# ATBTLC1000WLCSP register map
Vendor: Atmel Corp; Series: SAMB11; File version: TODO
CPU: CM0 r0p0, little endian, no MPU, no FPU, 2 interrupt priority bits
Address unit: 32 bits
Registers are 32-bit, read-write, reset 0x0 unless marked. A register's access mark holds for its fields unless they carry their own. Offsets are from the block's base; [hi:lo] are bit positions; {n}, {i} and the like mark numbered series.

## WDT0 — Watchdog0 Timer
Base 0x40008000
Same registers: WDT1 0x40009000
0x00 WDOGLOAD reset 0xFFFFFFFF — Watchdog Load Register
0x04 WDOGVALUE ro reset 0xFFFFFFFF — Watchdog Value Register
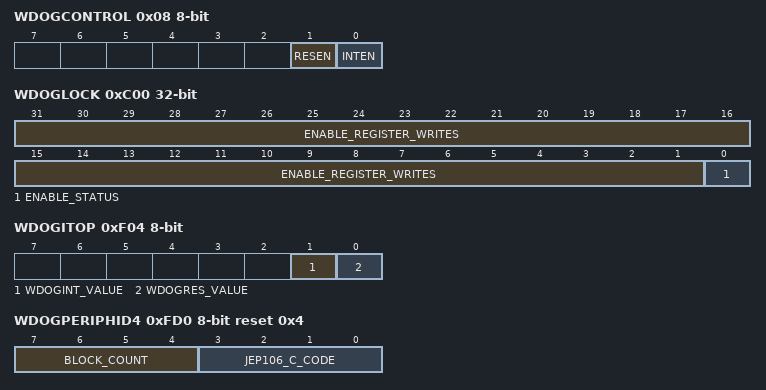
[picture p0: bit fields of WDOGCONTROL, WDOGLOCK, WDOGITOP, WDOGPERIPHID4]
0x08 WDOGCONTROL 8-bit — Watchdog Control Register
  [1] RESEN — Active High Enable Watchdog Reset Output
  [0] INTEN — Active High Enable Interrupt Event
0x0C WDOGINTCLR 8-bit wo (reset mask 0x1) — Watchdog Clear Interrupt Register
0x10 WDOGRIS 8-bit ro (reset mask 0x1) — Watchdog Raw Interrupt Status Register
0x14 WDOGMIS 8-bit ro (reset mask 0x1) — Watchdog Interrupt Status Register
0xC00 WDOGLOCK — Watchdog Lock Register (Write 0x1ACCE551 to enable write access to all other registers)
  [31:1] ENABLE_REGISTER_WRITES — Read back all 0s, write 0x1ACCE551 to enable write access to all other registers
  [0] ENABLE_STATUS — Read back of 1 indicates that write access is enabled
0xF00 WDOGITCR 8-bit — Watchdog Integration Test Control Register
  [0] ENABLE — Set HIGH to place watchdog into integration test mode
0xF04 WDOGITOP 8-bit — Watchdog Integration Test Output Set Register
  [1] WDOGINT_VALUE — Value output on WDOGINT when in Integration Test Mode
  [0] WDOGRES_VALUE — Value output on WDOGRES when in Integration Test Mode
0xFD0 WDOGPERIPHID4 8-bit ro reset 0x4 — Peripheral ID Register 4
  [7:4] BLOCK_COUNT, [3:0] JEP106_C_CODE
{0xFC0+4i} WDOGPERIPHID{i} 8-bit ro (i=5..7) — Peripheral ID Register {i}
0xFE0 WDOGPERIPHID0 8-bit ro reset 0x24 — Peripheral ID Register 0
  [7:0] PART_NUMBER — Part Number Bits 7:0
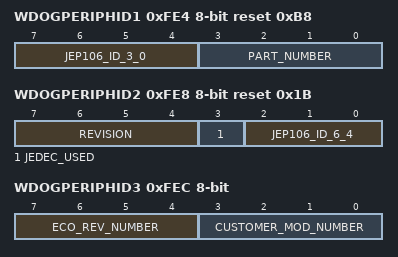
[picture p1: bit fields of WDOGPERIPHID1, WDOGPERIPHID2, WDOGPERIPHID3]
0xFE4 WDOGPERIPHID1 8-bit ro reset 0xB8 — Peripheral ID Register 1
  [7:4] JEP106_ID_3_0 — JEP106 ID Bits 3:0
  [3:0] PART_NUMBER — Part Number Bits 11:8
0xFE8 WDOGPERIPHID2 8-bit ro reset 0x1B — Peripheral ID Register 2
  [7:4] REVISION
  [3] JEDEC_USED
  [2:0] JEP106_ID_6_4 — JEP106 ID Bits 6:4
0xFEC WDOGPERIPHID3 8-bit ro — Peripheral ID Register 3
  [7:4] ECO_REV_NUMBER — ECO Revision Number
  [3:0] CUSTOMER_MOD_NUMBER — Customer Modification Number
0xFF0 WDOGPCELLID0 8-bit ro reset 0xD — Component ID Register 0
0xFF4 WDOGPCELLID1 8-bit ro reset 0xF0 — Component ID Register 1
0xFF8 WDOGPCELLID2 8-bit ro reset 0x5 — Component ID Register 2
0xFFC WDOGPCELLID3 8-bit ro reset 0xB1 — Component ID Register 3

## EFUSE_MISC_REGS0 — EFUSE Misc Registers
Base 0x4000A000
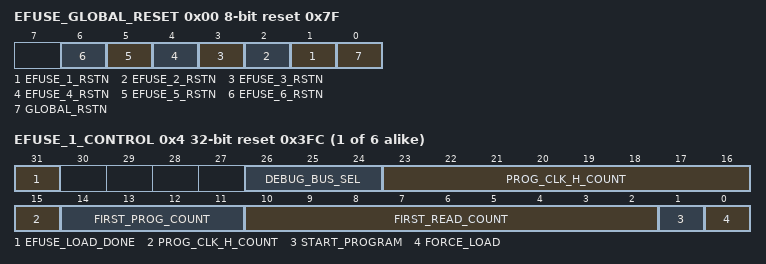
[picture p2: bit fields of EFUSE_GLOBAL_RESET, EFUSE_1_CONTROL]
0x00 EFUSE_GLOBAL_RESET 8-bit reset 0x7F — All individual software controllable resets. 0: Reset the selected function. 1: Normal operation.
  [n] EFUSE_{n}_RSTN (n=1..6) — EFUSE {n} Reset
  [0] GLOBAL_RSTN — Global Reset
{0x0+4i} EFUSE_{i}_CONTROL reset 0x3FC (i=1..6)
  [31] EFUSE_LOAD_DONE ro — Efuse Load Done Indication
  [26:24] DEBUG_BUS_SEL — EFUSE Debug Bus Selection
  [23:15] PROG_CLK_H_COUNT — First Clock High Count
  [14:11] FIRST_PROG_COUNT — First Program Count
  [10:2] FIRST_READ_COUNT
  [1] START_PROGRAM — When set to 1 will start programming EFUSE
  [0] FORCE_LOAD — Efuse Control Force Load
{0x1C+4i} EFUSE_1_PROG_{i} (i=0..3) — EFUSE_1_{i} Program Register
{0xC+0x20*i} EFUSE_{i}_STATUS_0 ro (i=1..6) — EFUSE_{i}_0 Status
{0x10+0x20*i} EFUSE_{i}_STATUS_1 ro (i=1..6) — EFUSE_{i}_1 Status
{0x14+0x20*i} EFUSE_{i}_STATUS_2 ro (i=1..6) — EFUSE_{i}_2 Status
{0x18+0x20*i} EFUSE_{i}_STATUS_3 ro (i=1..6) — EFUSE_{i}_3 Status
{0x3C+4i} EFUSE_2_PROG_{i} (i=0..3) — EFUSE_2_{i} Program Register
{0x5C+4i} EFUSE_3_PROG_{i} (i=0..3) — EFUSE_3_{i} Program Register
{0x7C+4i} EFUSE_4_PROG_{i} (i=0..3) — EFUSE_4_{i} Program Register
0x9C EFUSE_5_PROG_0 — EFUSE_4_0 Program Register
{0x9C+4i} EFUSE_5_PROG_{i} (i=1..3) — EFUSE_5_{i} Program Register
{0xBC+4i} EFUSE_6_PROG_{i} (i=0..3) — EFUSE_6_{i} Program Register
0xDC EFUSE_MISC_CTRL 8-bit ro — EFUSE 6 Control Register
  [0] OUT_OF_RESET — Read back the status of the eFuse out of reset
